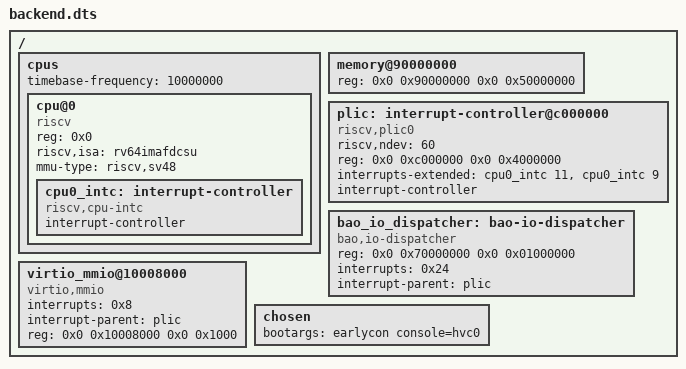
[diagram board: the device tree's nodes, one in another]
/dts-v1/;

/ {
	#address-cells = <0x2>;
	#size-cells = <0x2>;

	cpus {
		#address-cells = <0x1>;
		#size-cells = <0x0>;
		timebase-frequency = <10000000>;

		cpu@0 {
			device_type = "cpu";
			reg = <0x0>;
			status = "okay";
			compatible = "riscv";
			riscv,isa = "rv64imafdcsu";
			mmu-type = "riscv,sv48";

			cpu0_intc: interrupt-controller {
				#interrupt-cells = <0x1>;
				interrupt-controller;
				compatible = "riscv,cpu-intc";
			};
		};
	};

	memory@90000000 {
		device_type = "memory";
		reg = <0x0 0x90000000 0x0 0x50000000>;
	};

	plic: interrupt-controller@c000000 {
		riscv,ndev = <60>;
		reg = <0x0 0xc000000 0x0 0x4000000>;
		interrupts-extended = <
			&cpu0_intc 11 &cpu0_intc 9 
		>;
		interrupt-controller;
		compatible = "riscv,plic0";
		#interrupt-cells = <0x1>;
	};

	bao_io_dispatcher: bao-io-dispatcher {
		compatible = "bao,io-dispatcher";
		reg = <0x0 0x70000000 0x0 0x01000000>;
		interrupts = <0x24>;
		interrupt-parent = <&plic>;
	};

	virtio_mmio@10008000 {
		interrupts = <0x8>;
		interrupt-parent = <&plic>;
		reg = <0x0 0x10008000 0x0 0x1000>;
		compatible = "virtio,mmio";
	};

	chosen {
		bootargs = "earlycon console=hvc0";
	};

};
